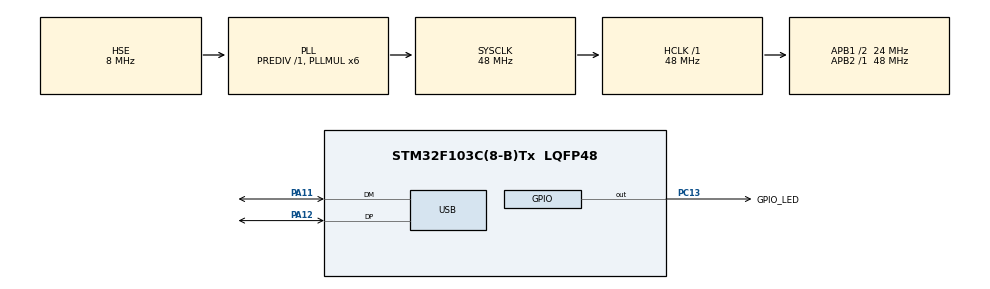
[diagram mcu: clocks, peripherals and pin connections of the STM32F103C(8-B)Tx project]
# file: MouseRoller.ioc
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Mcu.Family=STM32F1
Mcu.Name=STM32F103C(8-B)Tx
Mcu.Package=LQFP48
NVIC.PriorityGroup=NVIC_PRIORITYGROUP_4
NVIC.USB_LP_CAN1_RX0_IRQn=true\:0\:0\:false\:false\:true\:false\:true\:true
PA11.Mode=Device
PA11.Signal=USB_DM
PA12.Mode=Device
PA12.Signal=USB_DP
PA13.Mode=Serial_Wire
PA13.Signal=SYS_JTMS-SWDIO
PA14.Mode=Serial_Wire
PA14.Signal=SYS_JTCK-SWCLK
PC13-TAMPER-RTC.GPIO_Label=GPIO_LED
PC13-TAMPER-RTC.Signal=GPIO_Output
PC14-OSC32_IN.Mode=LSE-External-Oscillator
PC14-OSC32_IN.Signal=RCC_OSC32_IN
PC15-OSC32_OUT.Mode=LSE-External-Oscillator
PC15-OSC32_OUT.Signal=RCC_OSC32_OUT
PD0-OSC_IN.Mode=HSE-External-Oscillator
PD0-OSC_IN.Signal=RCC_OSC_IN
PD1-OSC_OUT.Mode=HSE-External-Oscillator
PD1-OSC_OUT.Signal=RCC_OSC_OUT
ProjectManager.HeapSize=0x200
ProjectManager.StackSize=0x400
ProjectManager.TargetToolchain=STM32CubeIDE
RCC.AHBFreq_Value=48000000
RCC.APB1CLKDivider=RCC_HCLK_DIV2
RCC.APB1Freq_Value=24000000
RCC.APB1TimFreq_Value=48000000
RCC.APB2Freq_Value=48000000
RCC.APB2TimFreq_Value=48000000
RCC.HCLKFreq_Value=48000000
RCC.PLLMUL=RCC_PLL_MUL6
RCC.SYSCLKFreq_VALUE=48000000
RCC.SYSCLKSource=RCC_SYSCLKSOURCE_PLLCLK
RCC.USBFreq_Value=48000000
USB_DEVICE.CLASS_NAME_FS=HID
USB_DEVICE.MANUFACTURER_STRING=wt47a
USB_DEVICE.USBD_SELF_POWERED=0
USB_DEVICE.VirtualMode=Hid
USB_DEVICE.VirtualModeFS=Hid_FS
VP_USB_DEVICE_VS_USB_DEVICE_HID_FS.Mode=HID_FS
board=custom

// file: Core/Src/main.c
/* USER CODE BEGIN Header */
/**
  ******************************************************************************
  * @file           : main.c
  * @brief          : Main program body
  ******************************************************************************
  * @attention
  *
  * Copyright (c) 2022 STMicroelectronics.
  * All rights reserved.
  *
  * This software is licensed under terms that can be found in the LICENSE file
  * in the root directory of this software component.
  * If no LICENSE file comes with this software, it is provided AS-IS.
  *
  ******************************************************************************
  */
/* USER CODE END Header */
#include "main.h"
#include "usb_device.h"

/* USER CODE BEGIN Includes */
#include "usbd_hid.h"

/* USER CODE END Includes */

/* USER CODE BEGIN PTD */
typedef struct {
	uint8_t btnLeft:1;
	uint8_t btnMiddle:1;
	uint8_t btnRigth:1;
	int8_t moveX;
	int8_t moveY;
	int8_t wheel;
	uint8_t wakeup1:1;
	uint8_t wakeup2:1;
} MyMouseReport_t;
/* USER CODE END PTD */

/* USER CODE BEGIN PD */
#define WHEEL_MOVES_SIZE 32
/* USER CODE END PD */

/* USER CODE BEGIN PV */

extern USBD_HandleTypeDef hUsbDeviceFS;
/* USER CODE END PV */

void SystemClock_Config(void);
static void MX_GPIO_Init(void);

int main(void)
{
  /* USER CODE BEGIN 1 */
  MyMouseReport_t mouseReport = {0};
  int8_t wheelMoves[WHEEL_MOVES_SIZE] = { 0, 1, 2, 3, 1, 4, -1, 0, 0, 0, 0, -3, -2, -1, 0, 0, 0, -1, 0, 0, 1, 1, 1, 0, 1, 1, 0, -2, -2, 0, -2, -2 };
  uint8_t wheelMovesIdx=0;

  /* USER CODE END 1 */

  /* MCU Configuration--------------------------------------------------------*/

  /* Reset of all peripherals, Initializes the Flash interface and the Systick. */
  HAL_Init();

  /* Configure the system clock */
  SystemClock_Config();

  /* Initialize all configured peripherals */
  MX_GPIO_Init();
  MX_USB_DEVICE_Init();

  /* Infinite loop */
  while (1)
  {

    /* USER CODE BEGIN 3 */
	HAL_GPIO_TogglePin(GPIO_LED_GPIO_Port, GPIO_LED_Pin);
	HAL_Delay(300);

	mouseReport.wheel = wheelMoves[wheelMovesIdx];
	wheelMovesIdx = (wheelMovesIdx +1) % WHEEL_MOVES_SIZE;
	USBD_HID_SendReport(&hUsbDeviceFS, (uint8_t*)(&mouseReport), sizeof(mouseReport));
  }
  /* USER CODE END 3 */
}

void SystemClock_Config(void)
{
  RCC_OscInitTypeDef RCC_OscInitStruct = {0};
  RCC_ClkInitTypeDef RCC_ClkInitStruct = {0};
  RCC_PeriphCLKInitTypeDef PeriphClkInit = {0};

  /** Initializes the RCC Oscillators according to the specified parameters
  * in the RCC_OscInitTypeDef structure.
  */
  RCC_OscInitStruct.OscillatorType = RCC_OSCILLATORTYPE_HSE;
  RCC_OscInitStruct.HSEState = RCC_HSE_ON;
  RCC_OscInitStruct.HSEPredivValue = RCC_HSE_PREDIV_DIV1;
  RCC_OscInitStruct.HSIState = RCC_HSI_ON;
  RCC_OscInitStruct.PLL.PLLState = RCC_PLL_ON;
  RCC_OscInitStruct.PLL.PLLSource = RCC_PLLSOURCE_HSE;
  RCC_OscInitStruct.PLL.PLLMUL = RCC_PLL_MUL6;
  if (HAL_RCC_OscConfig(&RCC_OscInitStruct) != HAL_OK)
  {
    Error_Handler();
  }

  /** Initializes the CPU, AHB and APB buses clocks
  */
  RCC_ClkInitStruct.ClockType = RCC_CLOCKTYPE_HCLK|RCC_CLOCKTYPE_SYSCLK
                              |RCC_CLOCKTYPE_PCLK1|RCC_CLOCKTYPE_PCLK2;
  RCC_ClkInitStruct.SYSCLKSource = RCC_SYSCLKSOURCE_PLLCLK;
  RCC_ClkInitStruct.AHBCLKDivider = RCC_SYSCLK_DIV1;
  RCC_ClkInitStruct.APB1CLKDivider = RCC_HCLK_DIV2;
  RCC_ClkInitStruct.APB2CLKDivider = RCC_HCLK_DIV1;

  if (HAL_RCC_ClockConfig(&RCC_ClkInitStruct, FLASH_LATENCY_1) != HAL_OK)
  {
    Error_Handler();
  }
  PeriphClkInit.PeriphClockSelection = RCC_PERIPHCLK_USB;
  PeriphClkInit.UsbClockSelection = RCC_USBCLKSOURCE_PLL;
  if (HAL_RCCEx_PeriphCLKConfig(&PeriphClkInit) != HAL_OK)
  {
    Error_Handler();
  }
}

static void MX_GPIO_Init(void)
{
  GPIO_InitTypeDef GPIO_InitStruct = {0};

  /* GPIO Ports Clock Enable */
  __HAL_RCC_GPIOC_CLK_ENABLE();
  __HAL_RCC_GPIOD_CLK_ENABLE();
  __HAL_RCC_GPIOA_CLK_ENABLE();
  __HAL_RCC_GPIOB_CLK_ENABLE();

  /*Configure GPIO pin Output Level */
  HAL_GPIO_WritePin(GPIO_LED_GPIO_Port, GPIO_LED_Pin, GPIO_PIN_RESET);

  /*Configure GPIO pin : GPIO_LED_Pin */
  GPIO_InitStruct.Pin = GPIO_LED_Pin;
  GPIO_InitStruct.Mode = GPIO_MODE_OUTPUT_PP;
  GPIO_InitStruct.Pull = GPIO_NOPULL;
  GPIO_InitStruct.Speed = GPIO_SPEED_FREQ_LOW;
  HAL_GPIO_Init(GPIO_LED_GPIO_Port, &GPIO_InitStruct);

  /*Configure GPIO pins : PA0 PA1 PA2 PA3
                           PA4 PA5 PA6 PA7
                           PA8 PA9 PA10 PA15 */
  GPIO_InitStruct.Pin = GPIO_PIN_0|GPIO_PIN_1|GPIO_PIN_2|GPIO_PIN_3
                          |GPIO_PIN_4|GPIO_PIN_5|GPIO_PIN_6|GPIO_PIN_7
                          |GPIO_PIN_8|GPIO_PIN_9|GPIO_PIN_10|GPIO_PIN_15;
  GPIO_InitStruct.Mode = GPIO_MODE_ANALOG;
  HAL_GPIO_Init(GPIOA, &GPIO_InitStruct);

  /*Configure GPIO pins : PB0 PB1 PB2 PB10
                           PB11 PB12 PB13 PB14
                           PB15 PB3 PB4 PB5
                           PB6 PB7 PB8 PB9 */
  GPIO_InitStruct.Pin = GPIO_PIN_0|GPIO_PIN_1|GPIO_PIN_2|GPIO_PIN_10
                          |GPIO_PIN_11|GPIO_PIN_12|GPIO_PIN_13|GPIO_PIN_14
                          |GPIO_PIN_15|GPIO_PIN_3|GPIO_PIN_4|GPIO_PIN_5
                          |GPIO_PIN_6|GPIO_PIN_7|GPIO_PIN_8|GPIO_PIN_9;
  GPIO_InitStruct.Mode = GPIO_MODE_ANALOG;
  HAL_GPIO_Init(GPIOB, &GPIO_InitStruct);

}

void Error_Handler(void)
{
  __disable_irq();
  while (1)
  {
  }
}
